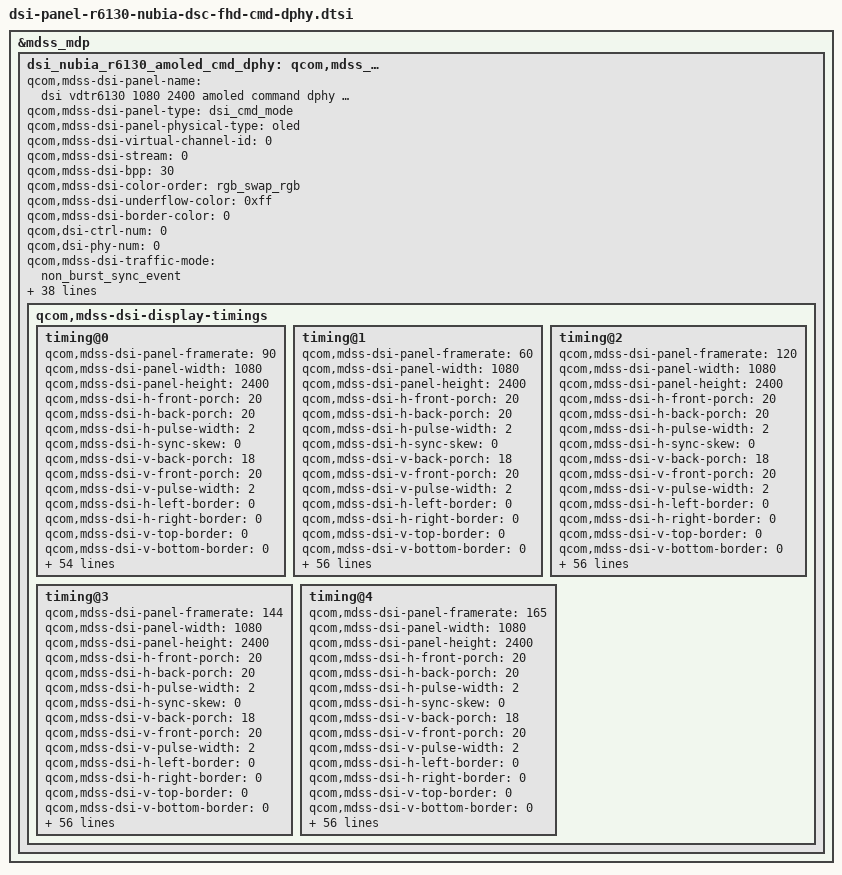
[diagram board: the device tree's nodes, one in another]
/* Copyright (c) 2016-2017, The Linux Foundation. All rights reserved.
 *
 * This program is free software; you can redistribute it and/or modify
 * it under the terms of the GNU General Public License version 2 and
 * only version 2 as published by the Free Software Foundation.
 *
 * This program is distributed in the hope that it will be useful,
 * but WITHOUT ANY WARRANTY; without even the implied warranty of
 * MERCHANTABILITY or FITNESS FOR A PARTICULAR PURPOSE.  See the
 * GNU General Public License for more details.
 */

&mdss_mdp {
	dsi_nubia_r6130_amoled_cmd_dphy: qcom,mdss_dsi_r6130_1080_2400_amoled_cmd {
		qcom,mdss-dsi-panel-name = "dsi vdtr6130 1080 2400 amoled command dphy panel";
		qcom,mdss-dsi-panel-type = "dsi_cmd_mode";
		qcom,mdss-dsi-panel-physical-type = "oled";
		qcom,mdss-dsi-virtual-channel-id = <0>;
		qcom,mdss-dsi-stream = <0>;
		qcom,mdss-dsi-bpp = <30>;
		qcom,mdss-dsi-color-order = "rgb_swap_rgb";
		qcom,mdss-dsi-underflow-color = <0xff>;
		qcom,mdss-dsi-border-color = <0>;

		qcom,dsi-ctrl-num = <0>;
		qcom,dsi-phy-num = <0>;

		qcom,mdss-dsi-traffic-mode = "non_burst_sync_event";
		qcom,mdss-dsi-lane-map = "lane_map_0123";
		qcom,mdss-dsi-bllp-eof-power-mode;
		qcom,mdss-dsi-bllp-power-mode;
		qcom,mdss-dsi-lane-0-state;
		qcom,mdss-dsi-lane-1-state;
		qcom,mdss-dsi-lane-2-state;
		qcom,mdss-dsi-lane-3-state; //dphy
		qcom,mdss-dsi-dma-trigger = "trigger_sw";
		qcom,mdss-dsi-mdp-trigger = "none";
		qcom,mdss-dsi-reset-sequence = <1 10>, <0 10>, <1 10>;
		qcom,mdss-dsi-tx-eot-append; //???
		qcom,mdss-dsi-rx-eot-ignore; //???

		/* brightness setting*/
		qcom,mdss-dsi-bl-pmic-control-type = "bl_ctrl_dcs";
		qcom,bl-dsc-cmd-state = "dsi_lp_mode";
		qcom,mdss-dsi-bl-min-level = <8>;
		qcom,mdss-dsi-bl-max-level = <2047>;
		qcom,mdss-brightness-max-level = <4080>;
		qcom,mdss-dsi-bl-inverted-dbv;

		qcom,mdss-dsi-te-pin-select = <1>;
		qcom,mdss-dsi-wr-mem-start = <0x2c>;
		qcom,mdss-dsi-wr-mem-continue = <0x3c>;

		qcom,panel-supply-entries = <&dsi_panel_pwr_supply>;

		qcom,platform-te-gpio = <&tlmm 82 0>;
		qcom,platform-reset-gpio = <&tlmm 24 0>;
		//qcom,panel-lhbm-gpio = <&tlmm 55 0>;
		qcom,panel-dvdd-1p2-gpio = <&tlmm 83 0>;

		qcom,mdss-dsi-te-dcs-command = <1>;
		qcom,mdss-dsi-te-check-enable;
		qcom,mdss-dsi-te-using-te-pin;
		//qcom,mdss-dsi-t-clk-post = <0x17>;
		//qcom,mdss-dsi-t-clk-pre = <0x18>;

		/* HDR Setting */
		qcom,mdss-dsi-panel-hdr-enabled;
		qcom,mdss-dsi-panel-hdr-color-primaries = <14500 15500 32000
			17000 15500 30000 8000 3000>;
		qcom,mdss-dsi-panel-peak-brightness = <4200000>;
		qcom,mdss-dsi-panel-blackness-level = <3230>;


		qcom,mdss-pan-physical-width-dimension = <71>;
		qcom,mdss-pan-physical-height-dimension = <157>;

		//qcom,mdss-dsi-lp11-init;

		qcom,mdss-dsi-qsync-min-refresh-rate = <85>;
		//qcom,dsi-supported-qsync-min-fps-list = <45 75 105 120 132>;

		qcom,mdss-dsi-display-timings {
			timing@0 {
				qcom,mdss-dsi-panel-framerate = <90>;
				qcom,mdss-dsi-panel-width = <1080>;
				qcom,mdss-dsi-panel-height = <2400>;
				qcom,mdss-dsi-h-front-porch = <20>;
				qcom,mdss-dsi-h-back-porch = <20>;
				qcom,mdss-dsi-h-pulse-width = <2>;
				qcom,mdss-dsi-h-sync-skew = <0>;
				qcom,mdss-dsi-v-back-porch = <18>;
				qcom,mdss-dsi-v-front-porch = <20>;
				qcom,mdss-dsi-v-pulse-width = <2>;
				qcom,mdss-dsi-h-left-border = <0>;
				qcom,mdss-dsi-h-right-border = <0>;
				qcom,mdss-dsi-v-top-border = <0>;
				qcom,mdss-dsi-v-bottom-border = <0>;
				qcom,mdss-mdp-transfer-time-us = <8000>;
				qcom,mdss-dsi-panel-jitter = <0x3C 0x0a>;

				qcom,mdss-dsi-on-command = [
					//39 01 00 00 00 00 02 59 09 //demura on
					39 01 00 00 00 00 02 55 10 //skin
					39 01 00 00 00 00 02 03 01
					39 01 00 00 00 00 02 35 00
					39 01 00 00 00 00 02 53 28
					39 01 00 00 00 00 03 51 00 FF
					39 01 00 00 00 00 02 6C 02 //60/90gamma
					39 01 00 00 00 00 02 6D 00
					39 01 00 00 00 00 02 6F 02
					39 01 00 00 00 00 5F 70 12 00 00 AB 30 80 09 60 04 38 00 28 02 1C 02 1C 02 00 02 0E 00 20 03 DD 00 07 00 0C 02 77 02 8B 18 00 10 F0 07 10 20 00 06 0F 0F 33 0E 1C 2A 38 46 54 62 69 70 77 79 7B 7D 7E 02 02 22 00 2A 40 2A BE 3A FC 3A FA 3A F8 3B 38 3B 78 3B B6 4B B6 4B F4 4B F4 6C 34 84 74 00 00 00 00 00 00
					39 01 00 00 00 00 03 F0 AA 10
					39 01 00 00 00 00 10 D0 84 15 50 14 A0 00 29 4B 1E 50 23 00 4B 23 51 //SWire
					39 01 00 00 00 00 16 B1 01 38 00 14 00 1C 00 01 66 00 14 00 14 00 01 66 00 14 05 CC 00 //VFP
					39 01 00 00 00 00 02 B3 C7 //SRAM data keep when DIC in SLPIN mode
					39 01 00 00 00 00 02 C3 44
					39 01 00 00 00 00 03 F0 AA 12
					39 01 00 00 00 00 0A B2 5B 5B 5B 5B 5B 5B 59 59 59
					39 01 00 00 00 00 03 F0 AA 13
					39 01 00 00 00 00 18 D3 0E 81 0E 81 0E 01 0C C3 09 06 00 60 00 53 00 3A 00 0C 00 0C 07 00 54 //EM
					39 01 00 00 00 00 03 F0 AA 14
					39 01 00 00 00 00 03 B2 03 33
					39 01 00 00 00 00 0D B4 00 33 00 00 00 3E 00 00 00 3E 00 00
					39 01 00 00 00 00 0A B5 00 09 09 09 09 09 09 06 01
					39 01 00 00 00 00 07 B9 00 00 08 09 09 09
					39 01 00 00 00 00 0D BC 10 00 00 06 11 09 3B 09 47 09 47 00
					39 01 00 00 00 00 0D BE 10 10 00 08 22 09 19 09 25 09 25 00
					39 01 00 00 00 00 03 F0 AA 15
					39 01 00 00 00 00 07 B5 25 41 00 23 00 00
					39 01 00 00 00 00 03 BC 07 00
					39 01 00 00 00 00 03 FF 5A 80
					39 01 00 00 00 00 02 65 14
					39 01 00 00 00 00 04 FA 08 08 08
					39 01 00 00 00 00 02 65 0E
					39 01 00 00 00 00 02 FA 10
					39 01 00 00 00 00 02 65 01
					39 01 00 00 00 00 03 F8 06 34 //esd
					39 01 00 00 00 00 03 FF 5A 81
					39 01 00 00 00 00 02 65 05
					39 01 00 00 00 00 02 F3 0F
					39 01 00 00 00 00 03 F0 AA 00//Lock Page CMD2
					39 01 00 00 00 00 03 FF 5A 00//Lock Page CMD3
					39 01 00 00 78 00 02 11 00
					39 01 00 00 00 00 02 29 00
				];

				qcom,mdss-dsi-timing-switch-command = [
					39 01 00 00 00 00 02 6C 02
					39 01 00 00 00 00 03 F0 AA 10
					39 01 00 00 00 00 16 B1 01 38 00 14 00 1C 00 01 66 00 14 00 14 00 01 66 00 14 05 CC 00
					39 01 00 00 00 00 03 F0 AA 13
					39 01 00 00 00 00 18 D3 0E 81 0E 81 0E 01 0C C3 09 06 00 60 00 53 00 3A 00 0C 00 0C 07 00 54
					39 01 00 00 14 00 03 F0 AA 00
				];

				qcom,mdss-dsi-off-command = [
					05 01 00 00 00 00 02 28 00
					05 01 00 00 64 00 02 10 00];
				qcom,mdss-dsi-on-command-state = "dsi_lp_mode";
				//qcom,mdss-dsi-timing-switch-command-state = "dsi_lp_mode";
				qcom,mdss-dsi-off-command-state = "dsi_lp_mode";

				/* Qsync function */
				qcom,mdss-dsi-qsync-on-commands = [
					39 01 00 00 00 00 03 F0 AA 13
					39 01 00 00 00 00 18 D3 0E 81 0E 81 0E 01 0C C3 09 06 00 60 00 60 00 60 00 0C 00 0C 07 00 00
					39 01 00 00 00 00 03 F0 AA 10
					39 01 00 00 00 00 0C BB 00 4C 00 01 FF 01 32 01 6E 00 7A
					39 01 00 00 00 00 02 BB 01
				];
				qcom,mdss-dsi-qsync-off-commands = [
					39 01 00 00 00 00 03 F0 AA 10
					39 01 00 00 00 00 02 BB 00
					39 01 00 00 00 00 03 F0 AA 13
					39 01 00 00 00 00 18 D3 0E 81 0E 81 0E 01 0C C3 09 06 00 60 00 53 00 3A 00 0C 00 0C 07 00 54
				];
				qcom,mdss-dsi-qsync-on-commands-state = "dsi_lp_mode";
				qcom,mdss-dsi-qsync-off-commands-state = "dsi_lp_mode";

				/* ACL function */
				nubia,mdss-dsi-cabc-command-off = [
					15 01 00 00 00 00 02 55 00];
				nubia,mdss-dsi-cabc-command-level1 = [
					15 01 00 00 00 00 02 55 11];
				nubia,mdss-dsi-cabc-command-level2 = [
					15 01 00 00 00 00 02 55 12];
				nubia,mdss-dsi-cabc-command-level3 = [
					15 01 00 00 00 00 02 55 13];
				nubia,mdss-dsi-cabc-command-off-state = "dsi_lp_mode";
				nubia,mdss-dsi-cabc-command-level1-state = "dsi_lp_mode";
				nubia,mdss-dsi-cabc-command-level2-state = "dsi_lp_mode";
				nubia,mdss-dsi-cabc-command-level3-state = "dsi_lp_mode";

				/* AOD function */
				qcom,mdss-dsi-nolp-command = [
					39 01 00 00 00 00 02 38 00
					39 01 00 00 00 00 02 6C 02
					39 01 00 00 00 00 03 F0 AA 10
					39 01 00 00 00 00 16 B1 01 39 00 14 00 14 00 01 66 00 14 00 14 00 01 66 00 14 05 CC 00
					39 01 00 00 00 00 03 F0 AA 13
					39 01 00 00 00 00 18 D3 0E 81 0E 81 0E 01 0C C3 09 06 00 60 00 53 00 3A 00 0C 00 0C 07 00 54
					39 01 00 00 14 00 03 F0 AA 00
				];

				qcom,mdss-dsi-lp1-command = [
					39 01 00 00 14 00 02 6C 00
					39 01 00 00 00 00 02 39 00
					39 01 00 00 00 00 02 6D 00];
				qcom,mdss-dsi-nolp-command-state = "dsi_lp_mode";
				qcom,mdss-dsi-lp1-command-state = "dsi_lp_mode";

				/* Local HBM function */
				nubia,mdss-dsi-lhbm-fp-command-on = [];
				nubia,mdss-dsi-lhbm-fp-command-off = [];
				nubia,mdss-dsi-lhbm-fp-command-on-state = "dsi_lp_mode";
				nubia,mdss-dsi-lhbm-fp-command-off-state = "dsi_lp_mode";

				/* DSC parameter */
				qcom,mdss-dsi-h-sync-pulse = <0>;
				qcom,compression-mode = "dsc";
				qcom,mdss-dsc-slice-height = <40>;
				qcom,mdss-dsc-slice-width = <540>;
				qcom,mdss-dsc-slice-per-pkt = <2>;
				qcom,mdss-dsc-bit-per-component = <10>;
				qcom,mdss-dsc-bit-per-pixel = <8>;
				qcom,mdss-dsc-block-prediction-enable;
			};

			timing@1 {
				qcom,mdss-dsi-panel-framerate = <60>;
				qcom,mdss-dsi-panel-width = <1080>;
				qcom,mdss-dsi-panel-height = <2400>;
				qcom,mdss-dsi-h-front-porch = <20>;
				qcom,mdss-dsi-h-back-porch = <20>;
				qcom,mdss-dsi-h-pulse-width = <2>;
				qcom,mdss-dsi-h-sync-skew = <0>;
				qcom,mdss-dsi-v-back-porch = <18>;
				qcom,mdss-dsi-v-front-porch = <20>;
				qcom,mdss-dsi-v-pulse-width = <2>;
				qcom,mdss-dsi-h-left-border = <0>;
				qcom,mdss-dsi-h-right-border = <0>;
				qcom,mdss-dsi-v-top-border = <0>;
				qcom,mdss-dsi-v-bottom-border = <0>;
				qcom,mdss-mdp-transfer-time-us = <14500>;
				qcom,mdss-dsi-panel-jitter = <0x3C 0x0a>;

				qcom,mdss-dsi-on-command = [
					//39 01 00 00 00 00 02 59 09 //demura on
					39 01 00 00 00 00 02 55 10 //skin
					39 01 00 00 00 00 02 03 01
					39 01 00 00 00 00 02 35 00
					39 01 00 00 00 00 02 53 28
					39 01 00 00 00 00 03 51 00 FF
					39 01 00 00 00 00 02 6C 02
					39 01 00 00 00 00 02 6D 00
					39 01 00 00 00 00 02 6F 02
					39 01 00 00 00 00 5F 70 12 00 00 AB 30 80 09 60 04 38 00 28 02 1C 02 1C 02 00 02 0E 00 20 03 DD 00 07 00 0C 02 77 02 8B 18 00 10 F0 07 10 20 00 06 0F 0F 33 0E 1C 2A 38 46 54 62 69 70 77 79 7B 7D 7E 02 02 22 00 2A 40 2A BE 3A FC 3A FA 3A F8 3B 38 3B 78 3B B6 4B B6 4B F4 4B F4 6C 34 84 74 00 00 00 00 00 00
					39 01 00 00 00 00 03 F0 AA 10
					39 01 00 00 00 00 10 D0 84 15 50 14 A0 00 29 4B 1E 50 23 00 4B 23 51
					39 01 00 00 00 00 16 B1 01 38 00 14 00 1C 00 01 66 00 14 01 FC 00 01 66 00 14 0D 6C 00
					39 01 00 00 00 00 02 B3 C7 //SRAM data keep when DIC in SLPIN mode
					39 01 00 00 00 00 02 C3 44
					39 01 00 00 00 00 03 F0 AA 12
					39 01 00 00 00 00 0A B2 5B 5B 5B 5B 5B 5B 59 59 59
					39 01 00 00 00 00 03 F0 AA 13
					39 01 00 00 00 00 18 D3 15 C2 15 C2 15 02 13 25 0D 8A 00 90 00 7D 00 57 00 0C 00 0C 0B 00 7E
					39 01 00 00 00 00 03 F0 AA 14
					39 01 00 00 00 00 03 B2 03 33
					39 01 00 00 00 00 0D B4 00 33 00 00 00 3E 00 00 00 3E 00 00
					39 01 00 00 00 00 0A B5 00 09 09 09 09 09 09 06 01
					39 01 00 00 00 00 07 B9 00 00 08 09 09 09
					39 01 00 00 00 00 0D BC 10 00 00 06 11 09 3B 09 47 09 47 00
					39 01 00 00 00 00 0D BE 10 10 00 08 22 09 19 09 25 09 25 00
					39 01 00 00 00 00 03 F0 AA 15
					39 01 00 00 00 00 07 B5 25 41 00 23 00 00
					39 01 00 00 00 00 03 BC 07 00
					39 01 00 00 00 00 03 FF 5A 80
					39 01 00 00 00 00 02 65 14
					39 01 00 00 00 00 04 FA 08 08 08
					39 01 00 00 00 00 02 65 0E
					39 01 00 00 00 00 02 FA 10
					39 01 00 00 00 00 02 65 01
					39 01 00 00 00 00 03 F8 06 34 //esd
					39 01 00 00 00 00 03 FF 5A 81
					39 01 00 00 00 00 02 65 05
					39 01 00 00 00 00 02 F3 0F
					39 01 00 00 00 00 03 F0 AA 00
					39 01 00 00 00 00 03 FF 5A 00
					39 01 00 00 78 00 02 11 00
					39 01 00 00 00 00 02 29 00
				];
				qcom,mdss-dsi-timing-switch-command = [
					39 01 00 00 00 00 02 6C 02
					39 01 00 00 00 00 03 F0 AA 10
					39 01 00 00 00 00 16 B1 01 38 00 14 00 1C 00 01 66 00 14 01 FC 00 01 66 00 14 0D 6C 00
					39 01 00 00 00 00 03 F0 AA 13
					39 01 00 00 00 00 18 D3 15 C2 15 C2 15 02 13 25 0D 8A 00 90 00 7D 00 57 00 0C 00 0C 0B 00 7E
					39 01 00 00 14 00 03 F0 AA 00
				];
				qcom,mdss-dsi-off-command = [
					05 01 00 00 00 00 02 28 00
					05 01 00 00 64 00 02 10 00];
				qcom,mdss-dsi-on-command-state = "dsi_lp_mode";
				qcom,mdss-dsi-timing-switch-command-state = "dsi_lp_mode";
				qcom,mdss-dsi-off-command-state = "dsi_lp_mode";

				/* Qsync function */
				qcom,mdss-dsi-qsync-on-commands = [
					39 01 00 00 00 00 03 F0 AA 13
					39 01 00 00 00 00 18 D3 15 C2 15 C2 15 02 13 25 0D 8A 00 90 00 90 00 90 00 0C 00 0C 0B 00 00
					39 01 00 00 00 00 03 F0 AA 10
					39 01 00 00 00 00 0C BB 00 4C 00 01 FF 01 32 01 6E 00 7A
					39 01 00 00 00 00 02 BB 01
				];
				qcom,mdss-dsi-qsync-off-commands = [
					39 01 00 00 00 00 03 F0 AA 10
					39 01 00 00 00 00 02 BB 00
					39 01 00 00 00 00 03 F0 AA 13
					39 01 00 00 00 00 18 D3 15 C2 15 C2 15 02 13 25 0D 8A 00 90 00 7D 00 57 00 0C 00 0C 0B 00 7E
				];
				qcom,mdss-dsi-qsync-on-commands-state = "dsi_lp_mode";
				qcom,mdss-dsi-qsync-off-commands-state = "dsi_lp_mode";

				/* ACL function */
				nubia,mdss-dsi-cabc-command-off = [
					15 01 00 00 00 00 02 55 00];
				nubia,mdss-dsi-cabc-command-level1 = [
					15 01 00 00 00 00 02 55 11];
				nubia,mdss-dsi-cabc-command-level2 = [
					15 01 00 00 00 00 02 55 12];
				nubia,mdss-dsi-cabc-command-level3 = [
					15 01 00 00 00 00 02 55 13];
				nubia,mdss-dsi-cabc-command-off-state = "dsi_lp_mode";
				nubia,mdss-dsi-cabc-command-level1-state = "dsi_lp_mode";
				nubia,mdss-dsi-cabc-command-level2-state = "dsi_lp_mode";
				nubia,mdss-dsi-cabc-command-level3-state = "dsi_lp_mode";

				/* AOD function */
				qcom,mdss-dsi-nolp-command = [
					39 01 00 00 00 00 02 38 00
					39 01 00 00 00 00 02 6C 02
					39 01 00 00 00 00 03 F0 AA 10
					39 01 00 00 00 00 16 B1 01 39 00 14 00 14 00 01 66 00 14 01 FC 00 01 66 00 14 0D 6C 00
					39 01 00 00 00 00 03 F0 AA 13
					39 01 00 00 00 00 18 D3 15 C2 15 C2 15 02 13 25 0D 8A 00 90 00 7D 00 57 00 0C 00 0C 0B 00 7E
					39 01 00 00 14 00 03 F0 AA 00
				];

				qcom,mdss-dsi-lp1-command = [
					39 01 00 00 14 00 02 6C 00
					39 01 00 00 00 00 02 39 00
					39 01 00 00 00 00 02 6D 00];
				qcom,mdss-dsi-nolp-command-state = "dsi_lp_mode";
				qcom,mdss-dsi-lp1-command-state = "dsi_lp_mode";

				/* Local HBM function */
				nubia,mdss-dsi-lhbm-fp-command-on = [];
				nubia,mdss-dsi-lhbm-fp-command-off = [];
				nubia,mdss-dsi-lhbm-fp-command-on-state = "dsi_lp_mode";
				nubia,mdss-dsi-lhbm-fp-command-off-state = "dsi_lp_mode";

				/* DSC parameter */
				qcom,mdss-dsi-h-sync-pulse = <0>;
				qcom,compression-mode = "dsc";
				qcom,mdss-dsc-slice-height = <40>;
				qcom,mdss-dsc-slice-width = <540>;
				qcom,mdss-dsc-slice-per-pkt = <2>;
				qcom,mdss-dsc-bit-per-component = <10>;
				qcom,mdss-dsc-bit-per-pixel = <8>;
				qcom,mdss-dsc-block-prediction-enable;
			};

			timing@2 {
				qcom,mdss-dsi-panel-framerate = <120>;
				qcom,mdss-dsi-panel-width = <1080>;
				qcom,mdss-dsi-panel-height = <2400>;
				qcom,mdss-dsi-h-front-porch = <20>;
				qcom,mdss-dsi-h-back-porch = <20>;
				qcom,mdss-dsi-h-pulse-width = <2>;
				qcom,mdss-dsi-h-sync-skew = <0>;
				qcom,mdss-dsi-v-back-porch = <18>;
				qcom,mdss-dsi-v-front-porch = <20>;
				qcom,mdss-dsi-v-pulse-width = <2>;
				qcom,mdss-dsi-h-left-border = <0>;
				qcom,mdss-dsi-h-right-border = <0>;
				qcom,mdss-dsi-v-top-border = <0>;
				qcom,mdss-dsi-v-bottom-border = <0>;
				qcom,mdss-mdp-transfer-time-us = <6000>;
				qcom,mdss-dsi-panel-jitter = <0x3C 0x0a>;

				qcom,mdss-dsi-on-command = [
					//39 01 00 00 00 00 02 59 09 //demura on
					39 01 00 00 00 00 02 55 10 //skin
					39 01 00 00 00 00 02 03 01
					39 01 00 00 00 00 02 35 00
					39 01 00 00 00 00 02 53 28
					39 01 00 00 00 00 03 51 00 FF
					39 01 00 00 00 00 02 6C 01 //144/120gamma
					39 01 00 00 00 00 02 6D 00
					39 01 00 00 00 00 02 6F 02
					39 01 00 00 00 00 5F 70 12 00 00 AB 30 80 09 60 04 38 00 28 02 1C 02 1C 02 00 02 0E 00 20 03 DD 00 07 00 0C 02 77 02 8B 18 00 10 F0 07 10 20 00 06 0F 0F 33 0E 1C 2A 38 46 54 62 69 70 77 79 7B 7D 7E 02 02 22 00 2A 40 2A BE 3A FC 3A FA 3A F8 3B 38 3B 78 3B B6 4B B6 4B F4 4B F4 6C 34 84 74 00 00 00 00 00 00
					39 01 00 00 00 00 03 F0 AA 10
					39 01 00 00 00 00 10 D0 84 15 50 14 A0 00 29 4B 1E 50 23 00 4B 23 51
					39 01 00 00 00 00 16 B1 01 38 00 14 00 1C 00 01 66 00 14 01 FC 00 01 66 00 14 0D 6C 00
					39 01 00 00 00 00 02 B3 C7
					39 01 00 00 00 00 02 C3 44
					39 01 00 00 00 00 03 F0 AA 12
					39 01 00 00 00 00 0A B2 5B 5B 5B 5B 5B 5B 59 59 59
					39 01 00 00 00 00 03 F0 AA 13
					39 01 00 00 00 00 18 CE 0A E1 0A E1 0A 81 09 92 06 C5 00 48 00 3E 00 2B 00 0C 00 0C 05 00 3F
					39 01 00 00 00 00 03 F0 AA 14
					39 01 00 00 00 00 03 B2 03 33
					39 01 00 00 00 00 0D B4 00 33 00 00 00 3E 00 00 00 3E 00 00
					39 01 00 00 00 00 0A B5 00 09 09 09 09 09 09 06 01
					39 01 00 00 00 00 07 B9 00 00 08 09 09 09
					39 01 00 00 00 00 0D BC 10 00 00 06 11 09 3B 09 47 09 47 00
					39 01 00 00 00 00 0D BE 10 10 00 08 22 09 19 09 25 09 25 00
					39 01 00 00 00 00 03 F0 AA 15
					39 01 00 00 00 00 07 B5 25 41 00 23 00 00
					39 01 00 00 00 00 03 BC 07 00
					39 01 00 00 00 00 03 FF 5A 80
					39 01 00 00 00 00 02 65 14
					39 01 00 00 00 00 04 FA 08 08 08
					39 01 00 00 00 00 02 65 0E
					39 01 00 00 00 00 02 FA 10
					39 01 00 00 00 00 02 65 01
					39 01 00 00 00 00 03 F8 06 34 //esd
					39 01 00 00 00 00 03 FF 5A 81
					39 01 00 00 00 00 02 65 05
					39 01 00 00 00 00 02 F3 0F
					39 01 00 00 00 00 03 F0 AA 00//Lock Page CMD2
					39 01 00 00 00 00 03 FF 5A 00//Lock Page CMD3
					39 01 00 00 78 00 02 11 00
					39 01 00 00 00 00 02 29 00
				];
				qcom,mdss-dsi-timing-switch-command = [
					39 01 00 00 00 00 02 6C 01
					39 01 00 00 00 00 03 F0 AA 10
					39 01 00 00 00 00 16 B1 01 38 00 14 00 1C 00 01 66 00 14 01 FC 00 01 66 00 14 0D 6C 00
					39 01 00 00 00 00 03 F0 AA 13
					39 01 00 00 00 00 18 CE 0A E1 0A E1 0A 81 09 92 06 C5 00 48 00 3E 00 2B 00 0C 00 0C 05 00 3F
					39 01 00 00 14 00 03 F0 AA 00
				];
				qcom,mdss-dsi-off-command = [
					05 01 00 00 00 00 02 28 00
					05 01 00 00 64 00 02 10 00];
				qcom,mdss-dsi-on-command-state = "dsi_lp_mode";
				qcom,mdss-dsi-timing-switch-command-state = "dsi_lp_mode";
				qcom,mdss-dsi-off-command-state = "dsi_lp_mode";

				/* Qsync function */
				qcom,mdss-dsi-qsync-on-commands = [
					39 01 00 00 00 00 03 F0 AA 13
					39 01 00 00 00 00 18 CE 0A E1 0A E1 0A 81 09 92 06 C5 00 48 00 48 00 48 00 0C 00 0C 05 00 00
					39 01 00 00 00 00 03 F0 AA 10
					39 01 00 00 00 00 0C BB 00 4C 00 01 FF 01 32 00 7A 01 6E
					39 01 00 00 00 00 02 BB 01
				];
				qcom,mdss-dsi-qsync-off-commands = [
					39 01 00 00 00 00 03 F0 AA 10
					39 01 00 00 00 00 02 BB 00
					39 01 00 00 00 00 03 F0 AA 13
					39 01 00 00 00 00 18 CE 0A E1 0A E1 0A 81 09 92 06 C5 00 48 00 3E 00 2B 00 0C 00 0C 05 00 3F
				];
				qcom,mdss-dsi-qsync-on-commands-state = "dsi_lp_mode";
				qcom,mdss-dsi-qsync-off-commands-state = "dsi_lp_mode";

				/* ACL function */
				nubia,mdss-dsi-cabc-command-off = [
					15 01 00 00 00 00 02 55 00];
				nubia,mdss-dsi-cabc-command-level1 = [
					15 01 00 00 00 00 02 55 11];
				nubia,mdss-dsi-cabc-command-level2 = [
					15 01 00 00 00 00 02 55 12];
				nubia,mdss-dsi-cabc-command-level3 = [
					15 01 00 00 00 00 02 55 13];
				nubia,mdss-dsi-cabc-command-off-state = "dsi_lp_mode";
				nubia,mdss-dsi-cabc-command-level1-state = "dsi_lp_mode";
				nubia,mdss-dsi-cabc-command-level2-state = "dsi_lp_mode";
				nubia,mdss-dsi-cabc-command-level3-state = "dsi_lp_mode";

				/* AOD function */
				qcom,mdss-dsi-nolp-command = [
					39 01 00 00 00 00 02 38 00
					39 01 00 00 00 00 02 6C 01
					39 01 00 00 00 00 03 F0 AA 10
					39 01 00 00 00 00 16 B1 01 39 00 14 00 14 00 01 66 00 14 01 FC 00 01 66 00 14 0D 6C 00
					39 01 00 00 00 00 03 F0 AA 13
					39 01 00 00 00 00 18 CE 0A E1 0A E1 0A 81 09 92 06 C5 00 48 00 3E 00 2B 00 0C 00 0C 05 00 3F
					39 01 00 00 14 00 03 F0 AA 00
				];

				qcom,mdss-dsi-lp1-command = [
					39 01 00 00 14 00 02 6C 00
					39 01 00 00 00 00 02 39 00
					39 01 00 00 00 00 02 6D 00];
				qcom,mdss-dsi-nolp-command-state = "dsi_lp_mode";
				qcom,mdss-dsi-lp1-command-state = "dsi_lp_mode";

				/* Local HBM function */
				nubia,mdss-dsi-lhbm-fp-command-on = [];
				nubia,mdss-dsi-lhbm-fp-command-off = [];
				nubia,mdss-dsi-lhbm-fp-command-on-state = "dsi_lp_mode";
				nubia,mdss-dsi-lhbm-fp-command-off-state = "dsi_lp_mode";

				/* DSC parameter */
				qcom,mdss-dsi-h-sync-pulse = <0>;
				qcom,compression-mode = "dsc";
				qcom,mdss-dsc-slice-height = <40>;
				qcom,mdss-dsc-slice-width = <540>;
				qcom,mdss-dsc-slice-per-pkt = <2>;
				qcom,mdss-dsc-bit-per-component = <10>;
				qcom,mdss-dsc-bit-per-pixel = <8>;
				qcom,mdss-dsc-block-prediction-enable;
			};

			timing@3 {
				qcom,mdss-dsi-panel-framerate = <144>;
				qcom,mdss-dsi-panel-width = <1080>;
				qcom,mdss-dsi-panel-height = <2400>;
				qcom,mdss-dsi-h-front-porch = <20>;
				qcom,mdss-dsi-h-back-porch = <20>;
				qcom,mdss-dsi-h-pulse-width = <2>;
				qcom,mdss-dsi-h-sync-skew = <0>;
				qcom,mdss-dsi-v-back-porch = <18>;
				qcom,mdss-dsi-v-front-porch = <20>;
				qcom,mdss-dsi-v-pulse-width = <2>;
				qcom,mdss-dsi-h-left-border = <0>;
				qcom,mdss-dsi-h-right-border = <0>;
				qcom,mdss-dsi-v-top-border = <0>;
				qcom,mdss-dsi-v-bottom-border = <0>;
				qcom,mdss-mdp-transfer-time-us = <6100>;
				qcom,mdss-dsi-panel-jitter = <0x3C 0x0a>;

				qcom,mdss-dsi-on-command = [
					//39 01 00 00 00 00 02 59 09 //demura on
					39 01 00 00 00 00 02 55 10 //skin
					39 01 00 00 00 00 02 03 01
					39 01 00 00 00 00 02 35 00
					39 01 00 00 00 00 02 53 28
					39 01 00 00 00 00 03 51 00 FF
					39 01 00 00 00 00 02 6C 01
					39 01 00 00 00 00 02 6D 00
					39 01 00 00 00 00 02 6F 02
					39 01 00 00 00 00 5F 70 12 00 00 AB 30 80 09 60 04 38 00 28 02 1C 02 1C 02 00 02 0E 00 20 03 DD 00 07 00 0C 02 77 02 8B 18 00 10 F0 07 10 20 00 06 0F 0F 33 0E 1C 2A 38 46 54 62 69 70 77 79 7B 7D 7E 02 02 22 00 2A 40 2A BE 3A FC 3A FA 3A F8 3B 38 3B 78 3B B6 4B B6 4B F4 4B F4 6C 34 84 74 00 00 00 00 00 00
					39 01 00 00 00 00 03 F0 AA 10
					39 01 00 00 00 00 10 D0 84 15 50 14 A0 00 29 4B 1E 50 23 00 4B 23 51
					39 01 00 00 00 00 16 B1 01 38 00 14 00 1C 00 01 66 00 14 00 14 00 01 66 00 14 05 CC 00
					39 01 00 00 00 00 02 B3 C7
					39 01 00 00 00 00 02 C3 44
					39 01 00 00 00 00 03 F0 AA 12
					39 01 00 00 00 00 0A B2 5B 5B 5B 5B 5B 5B 59 59 59
					39 01 00 00 00 00 03 F0 AA 13
					39 01 00 00 00 00 18 CE 09 11 09 11 08 C1 07 FA 05 A4 00 3C 00 34 00 24 00 0C 00 0C 04 00 35
					39 01 00 00 00 00 03 F0 AA 14
					39 01 00 00 00 00 03 B2 03 33
					39 01 00 00 00 00 0D B4 00 33 00 00 00 3E 00 00 00 3E 00 00
					39 01 00 00 00 00 0A B5 00 09 09 09 09 09 09 06 01
					39 01 00 00 00 00 07 B9 00 00 08 09 09 09
					39 01 00 00 00 00 0D BC 10 00 00 06 11 09 3B 09 47 09 47 00
					39 01 00 00 00 00 0D BE 10 10 00 08 22 09 19 09 25 09 25 00
					39 01 00 00 00 00 03 F0 AA 15
					39 01 00 00 00 00 07 B5 25 41 00 23 00 00
					39 01 00 00 00 00 03 BC 07 00
					39 01 00 00 00 00 03 FF 5A 80
					39 01 00 00 00 00 02 65 14
					39 01 00 00 00 00 04 FA 08 08 08
					39 01 00 00 00 00 02 65 0E
					39 01 00 00 00 00 02 FA 10
					39 01 00 00 00 00 02 65 01
					39 01 00 00 00 00 03 F8 06 34
					39 01 00 00 00 00 03 FF 5A 81
					39 01 00 00 00 00 02 65 05
					39 01 00 00 00 00 02 F3 0F
					39 01 00 00 00 00 03 F0 AA 00//Lock Page CMD2
					39 01 00 00 00 00 03 FF 5A 00//Lock Page CMD3
					39 01 00 00 78 00 02 11 00
					39 01 00 00 00 00 02 29 00
				];
				qcom,mdss-dsi-timing-switch-command = [
					39 01 00 00 00 00 02 6C 01
					39 01 00 00 00 00 03 F0 AA 10
					39 01 00 00 00 00 16 B1 01 38 00 14 00 1C 00 01 66 00 14 00 14 00 01 66 00 14 05 CC 00
					39 01 00 00 00 00 03 F0 AA 13
					39 01 00 00 00 00 18 CE 09 11 09 11 08 C1 07 FA 05 A4 00 3C 00 34 00 24 00 0C 00 0C 04 00 35
					39 01 00 00 14 00 03 F0 AA 00
				];

				qcom,mdss-dsi-off-command = [
					05 01 00 00 00 00 02 28 00
					05 01 00 00 64 00 02 10 00];
				qcom,mdss-dsi-on-command-state = "dsi_lp_mode";
				qcom,mdss-dsi-timing-switch-command-state = "dsi_lp_mode";
				qcom,mdss-dsi-off-command-state = "dsi_lp_mode";

				/* Qsync function */
				qcom,mdss-dsi-qsync-on-commands = [
					39 01 00 00 00 00 03 F0 AA 13
					39 01 00 00 00 00 18 CE 09 11 09 11 08 C1 07 FA 05 A4 00 3C 00 3C 00 3C 00 0C 00 0C 04 00 00
					39 01 00 00 00 00 03 F0 AA 10
					39 01 00 00 00 00 0C BB 00 4C 00 01 FF 01 32 00 7A 01 6E
					39 01 00 00 00 00 02 BB 01
				];
				qcom,mdss-dsi-qsync-off-commands = [
					39 01 00 00 00 00 03 F0 AA 10
					39 01 00 00 00 00 02 BB 00
					39 01 00 00 00 00 03 F0 AA 13
					39 01 00 00 00 00 18 CE 09 11 09 11 08 C1 07 FA 05 A4 00 3C 00 34 00 24 00 0C 00 0C 04 00 35
				];
				qcom,mdss-dsi-qsync-on-commands-state = "dsi_lp_mode";
				qcom,mdss-dsi-qsync-off-commands-state = "dsi_lp_mode";

				/* ACL function */
				nubia,mdss-dsi-cabc-command-off = [
					15 01 00 00 00 00 02 55 00];
				nubia,mdss-dsi-cabc-command-level1 = [
					15 01 00 00 00 00 02 55 11];
				nubia,mdss-dsi-cabc-command-level2 = [
					15 01 00 00 00 00 02 55 12];
				nubia,mdss-dsi-cabc-command-level3 = [
					15 01 00 00 00 00 02 55 13];
				nubia,mdss-dsi-cabc-command-off-state = "dsi_lp_mode";
				nubia,mdss-dsi-cabc-command-level1-state = "dsi_lp_mode";
				nubia,mdss-dsi-cabc-command-level2-state = "dsi_lp_mode";
				nubia,mdss-dsi-cabc-command-level3-state = "dsi_lp_mode";

				/* AOD function */
				qcom,mdss-dsi-nolp-command = [
					39 01 00 00 00 00 02 38 00
					39 01 00 00 00 00 02 6C 01
					39 01 00 00 00 00 03 F0 AA 10
					39 01 00 00 00 00 16 B1 01 39 00 14 00 14 00 01 66 00 14 00 14 00 01 66 00 14 05 CC 00
					39 01 00 00 00 00 03 F0 AA 13
					39 01 00 00 00 00 18 CE 09 11 09 11 08 C1 07 FA 05 A4 00 3C 00 34 00 24 00 0C 00 0C 04 00 35
					39 01 00 00 14 00 03 F0 AA 00
				];

				qcom,mdss-dsi-lp1-command = [
					39 01 00 00 14 00 02 6C 00
					39 01 00 00 00 00 02 39 00
					39 01 00 00 00 00 02 6D 00];
				qcom,mdss-dsi-nolp-command-state = "dsi_lp_mode";
				qcom,mdss-dsi-lp1-command-state = "dsi_lp_mode";

				/* Local HBM function */
				nubia,mdss-dsi-lhbm-fp-command-on = [];
				nubia,mdss-dsi-lhbm-fp-command-off = [];
				nubia,mdss-dsi-lhbm-fp-command-on-state = "dsi_lp_mode";
				nubia,mdss-dsi-lhbm-fp-command-off-state = "dsi_lp_mode";

				/* DSC parameter */
				qcom,mdss-dsi-h-sync-pulse = <0>;
				qcom,compression-mode = "dsc";
				qcom,mdss-dsc-slice-height = <40>;
				qcom,mdss-dsc-slice-width = <540>;
				qcom,mdss-dsc-slice-per-pkt = <2>;
				qcom,mdss-dsc-bit-per-component = <10>;
				qcom,mdss-dsc-bit-per-pixel = <8>;
				qcom,mdss-dsc-block-prediction-enable;
			};

			timing@4 {
				qcom,mdss-dsi-panel-framerate = <165>;
				qcom,mdss-dsi-panel-width = <1080>;
				qcom,mdss-dsi-panel-height = <2400>;
				qcom,mdss-dsi-h-front-porch = <20>;
				qcom,mdss-dsi-h-back-porch = <20>;
				qcom,mdss-dsi-h-pulse-width = <2>;
				qcom,mdss-dsi-h-sync-skew = <0>;
				qcom,mdss-dsi-v-back-porch = <18>;
				qcom,mdss-dsi-v-front-porch = <20>;
				qcom,mdss-dsi-v-pulse-width = <2>;
				qcom,mdss-dsi-h-left-border = <0>;
				qcom,mdss-dsi-h-right-border = <0>;
				qcom,mdss-dsi-v-top-border = <0>;
				qcom,mdss-dsi-v-bottom-border = <0>;
				qcom,mdss-mdp-transfer-time-us = <6100>;
				qcom,mdss-dsi-panel-jitter = <0x3C 0x0a>;

				qcom,mdss-dsi-on-command = [
					//39 01 00 00 00 00 02 59 09 //demura on
					39 01 00 00 00 00 02 55 10 //skin
					39 01 00 00 00 00 02 03 01
					39 01 00 00 00 00 02 35 00
					39 01 00 00 00 00 02 53 28
					39 01 00 00 00 00 03 51 00 FF
					39 01 00 00 00 00 02 6C 00 //165
					39 01 00 00 00 00 02 6D 00
					39 01 00 00 00 00 02 6F 02
					39 01 00 00 00 00 5F 70 12 00 00 AB 30 80 09 60 04 38 00 28 02 1C 02 1C 02 00 02 0E 00 20 03 DD 00 07 00 0C 02 77 02 8B 18 00 10 F0 07 10 20 00 06 0F 0F 33 0E 1C 2A 38 46 54 62 69 70 77 79 7B 7D 7E 02 02 22 00 2A 40 2A BE 3A FC 3A FA 3A F8 3B 38 3B 78 3B B6 4B B6 4B F4 4B F4 6C 34 84 74 00 00 00 00 00 00
					39 01 00 00 00 00 03 F0 AA 10
					39 01 00 00 00 00 10 D0 84 15 50 14 A0 00 29 4B 1E 50 23 00 4B 23 51
					39 01 00 00 00 00 16 B1 01 38 00 14 00 1C 00 01 66 00 14 00 14 00 01 66 00 14 05 CC 00
					39 01 00 00 00 00 02 B3 C7
					39 01 00 00 00 00 02 C3 44
					39 01 00 00 00 00 03 F0 AA 12
					39 01 00 00 00 00 0A B2 5B 5B 5B 5B 5B 5B 59 59 59
					39 01 00 00 00 00 03 F0 AA 14
					39 01 00 00 00 00 03 B2 03 33
					39 01 00 00 00 00 0D B4 00 33 00 00 00 3E 00 00 00 3E 00 00
					39 01 00 00 00 00 0A B5 00 09 09 09 09 09 09 06 01
					39 01 00 00 00 00 07 B9 00 00 08 09 09 09
					39 01 00 00 00 00 0D BC 10 00 00 06 11 09 3B 09 47 09 47 00
					39 01 00 00 00 00 0D BE 10 10 00 08 22 09 19 09 25 09 25 00
					39 01 00 00 00 00 03 F0 AA 15
					39 01 00 00 00 00 07 B5 25 41 00 23 00 00
					39 01 00 00 00 00 03 BC 07 00
					39 01 00 00 00 00 03 FF 5A 80
					39 01 00 00 00 00 02 65 14
					39 01 00 00 00 00 04 FA 08 08 08
					39 01 00 00 00 00 02 65 0E
					39 01 00 00 00 00 02 FA 10
					39 01 00 00 00 00 02 65 01
					39 01 00 00 00 00 03 F8 06 34
					39 01 00 00 00 00 03 FF 5A 81
					39 01 00 00 00 00 02 65 05
					39 01 00 00 00 00 02 F3 0F
					39 01 00 00 00 00 03 F0 AA 00//Lock Page CMD2
					39 01 00 00 00 00 03 FF 5A 00//Lock Page CMD3
					39 01 00 00 78 00 02 11 00
					39 01 00 00 00 00 02 29 00
				];
				qcom,mdss-dsi-timing-switch-command = [
					39 01 00 00 00 00 02 6C 00
					39 01 00 00 00 00 03 F0 AA 10
					39 01 00 00 00 00 16 B1 01 38 00 14 00 1C 00 01 66 00 14 00 14 00 01 66 00 14 05 CC 00
					39 01 00 00 14 00 03 F0 AA 00
				];

				qcom,mdss-dsi-off-command = [
					05 01 00 00 00 00 02 28 00
					05 01 00 00 64 00 02 10 00];
				qcom,mdss-dsi-on-command-state = "dsi_lp_mode";
				qcom,mdss-dsi-timing-switch-command-state = "dsi_lp_mode";
				qcom,mdss-dsi-off-command-state = "dsi_lp_mode";

				/* Qsync function */
				qcom,mdss-dsi-qsync-on-commands = [
					39 01 00 00 00 00 03 F0 AA 13
					39 01 00 00 00 00 18 C9 09 11 09 11 08 C1 07 FA 05 A4 00 3C 00 34 00 34 00 0C 00 0C 03 00 00
					39 01 00 00 00 00 03 F0 AA 10
					39 01 00 00 00 00 08 B1 01 38 00 14 00 1C 00
					39 01 00 00 00 00 0C BB 00 4C 00 01 FF 00 99 01 6E 01 6E
					39 01 00 00 00 00 02 BB 01
				];
				qcom,mdss-dsi-qsync-off-commands = [
					39 01 00 00 00 00 03 F0 AA 10
					39 01 00 00 00 00 02 BB 00
					39 01 00 00 00 00 03 F0 AA 13
					39 01 00 00 00 00 18 C9 09 11 09 11 08 C1 07 FA 05 A4 00 3C 00 34 00 24 00 0C 00 0C 03 00 35
				];
				qcom,mdss-dsi-qsync-on-commands-state = "dsi_lp_mode";
				qcom,mdss-dsi-qsync-off-commands-state = "dsi_lp_mode";

				/* ACL function */
				nubia,mdss-dsi-cabc-command-off = [
					15 01 00 00 00 00 02 55 00];
				nubia,mdss-dsi-cabc-command-level1 = [
					15 01 00 00 00 00 02 55 11];
				nubia,mdss-dsi-cabc-command-level2 = [
					15 01 00 00 00 00 02 55 12];
				nubia,mdss-dsi-cabc-command-level3 = [
					15 01 00 00 00 00 02 55 13];
				nubia,mdss-dsi-cabc-command-off-state = "dsi_lp_mode";
				nubia,mdss-dsi-cabc-command-level1-state = "dsi_lp_mode";
				nubia,mdss-dsi-cabc-command-level2-state = "dsi_lp_mode";
				nubia,mdss-dsi-cabc-command-level3-state = "dsi_lp_mode";

				/* AOD function */
				qcom,mdss-dsi-nolp-command = [
					39 01 00 00 00 00 02 38 00];

				qcom,mdss-dsi-lp1-command = [
					39 01 00 00 14 00 02 6C 00
					39 01 00 00 00 00 02 39 00
					39 01 00 00 00 00 02 6D 00];
				qcom,mdss-dsi-nolp-command-state = "dsi_lp_mode";
				qcom,mdss-dsi-lp1-command-state = "dsi_lp_mode";

				/* Local HBM function */
				nubia,mdss-dsi-lhbm-fp-command-on = [];
				nubia,mdss-dsi-lhbm-fp-command-off = [];
				nubia,mdss-dsi-lhbm-fp-command-on-state = "dsi_lp_mode";
				nubia,mdss-dsi-lhbm-fp-command-off-state = "dsi_lp_mode";

				/* DSC parameter */
				qcom,mdss-dsi-h-sync-pulse = <0>;
				qcom,compression-mode = "dsc";
				qcom,mdss-dsc-slice-height = <40>;
				qcom,mdss-dsc-slice-width = <540>;
				qcom,mdss-dsc-slice-per-pkt = <2>;
				qcom,mdss-dsc-bit-per-component = <10>;
				qcom,mdss-dsc-bit-per-pixel = <8>;
				qcom,mdss-dsc-block-prediction-enable;
			};
		};
	};
};
